# HSM_HSM_PKE_CE010000h register map
Vendor: Texas Instruments
Peripheral module from a debugger description file (folder AM261x).
Registers are 32-bit, read-only, reset 0x0 unless marked. A register's access mark holds for its fields unless they carry their own. Offsets are as the file gives them; lines under a group give offsets from that group; [hi:lo] are bit positions; {n}, {i} and the like mark numbered series; 'fields as' and 'values as' point back to an identical list; <NAME> marks a mode.

## HSM_PKE
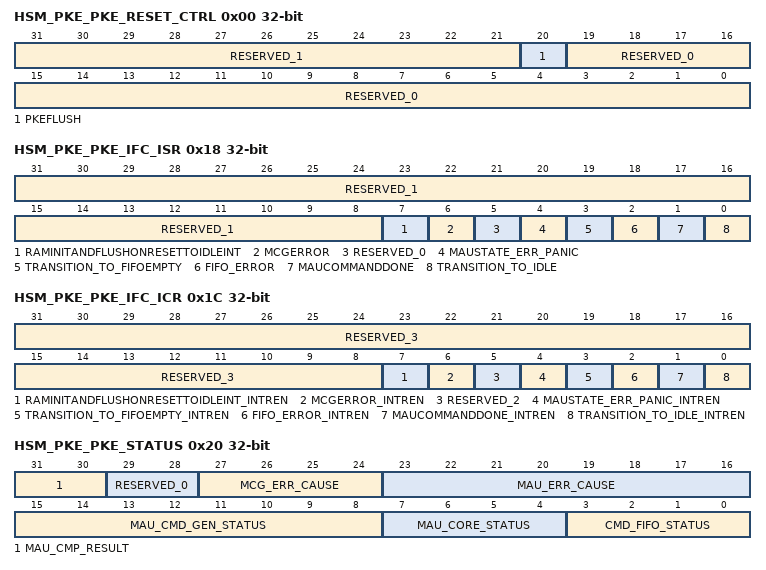
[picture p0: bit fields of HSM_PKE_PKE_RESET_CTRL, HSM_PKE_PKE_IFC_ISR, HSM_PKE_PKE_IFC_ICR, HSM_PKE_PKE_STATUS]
0x00 HSM_PKE_PKE_RESET_CTRL access per field — Reset control for Command FIFO and flush control for MAU Core. This register is not self-clearing.
  [31:21] RESERVED_1 wo — Set to zero on Write, ignore on Read.
  [20] PKEFLUSH rw — pkeFlush input to PKE[active high]. When set, this bit will assert the mauFlush input to MAU Core, resets command FIFO, issues reset to MCG. Flush sequence will complete some cycles after this bit is cleared. PKE will remain in flush state as long as this bit is asserted
  [19:0] RESERVED_0 wo — Set to zero on Write, ignore on Read.
0x18 HSM_PKE_PKE_IFC_ISR access per field — Interrupt Status Register. Writing a 1 to any bit in this register clears the associated interrupt.Cleared on pkeFlush.
  [31:8] RESERVED_1 wo — Set to zero on Write, ignore on Read.
  [7] RAMINITANDFLUSHONRESETTOIDLEINT rw — Asserted when SRAM initialization [when enabled] or FLUSH sequence after reset are completed. The PKE core will go into IDLE state when SRAM initialization [when enabled] and FLUSH sequence after resset finish.
  [6] MCGERROR rw — Asserted when MCG status indicates ERROR/PANIC. This interrupt is re-asserted when cleared if MCG status is MCG_ERROR/PANIC in PKE_STATUS register
  [5] RESERVED_0 wo — Set to zero on Write, ignore on Read.
  [4] MAUSTATE_ERR_PANIC rw — This interrupt is re-asserted when cleared if MAU Core Status is ERROR/PANIC in PKE_STATUS register.
  [3] TRANSITION_TO_FIFOEMPTY rw — This interrupt is asserted when FIFO transitions to empty. fifoEmpty gets asserted when pkeFlush is issued to the core triggering this interrupt. To disable interrupt just after pkeFlush, user can mask the corresponding bit in PKE_IFC_ICR register
  [2] FIFO_ERROR rw — This interrupt is re-asserted when cleared if FIFO Write Error is asserted in PKE_STATUS register.
  [1] MAUCOMMANDDONE rw — This interrupt is asserted when MAU status transition from BUSY to READY/ERROR/PANIC.
  [0] TRANSITION_TO_IDLE rw — Interrupt is generated on transition to idle [FIFO Empty and ![mauState==BUSY] & ![mcgState==BUSY]]
0x1C HSM_PKE_PKE_IFC_ICR access per field — Interrupt Control Register. Writing a 1 to any bit in this register enables the associated interrupt.
  [31:8] RESERVED_3 wo — Set to zero on Write, ignore on Read
  [7] RAMINITANDFLUSHONRESETTOIDLEINT_INTREN rw — Writing a 1 to any bit enables ram init and flush on reset to idle interrupt
  [6] MCGERROR_INTREN rw — Writing a 1 to any bit enables MCG Error interrupt
  [5] RESERVED_2 wo — Set to zero on Write, ignore on Read.
  [4] MAUSTATE_ERR_PANIC_INTREN rw — Writing a 1 to any bit enables MAU state is error panic interrupt
  [3] TRANSITION_TO_FIFOEMPTY_INTREN rw — Writing a 1 to any bit enables transition to FIFO empty interrupt
  [2] FIFO_ERROR_INTREN rw — Writing a 1 to any bit enables FIFO Error interrupt
  [1] MAUCOMMANDDONE_INTREN rw — Writing a 1 to any bit enables MAU command done interrupt
  [0] TRANSITION_TO_IDLE_INTREN rw — Writing a 1 to any bit enables transition to idle interrupt
0x20 HSM_PKE_PKE_STATUS access per field — Reports the status of the Command FIFO, Mau Core, and Mau Command Generator.
  [31:30] MAU_CMP_RESULT ro — Reflects the status of compare result when compare command is completed by MAU core only when the MAU command is issued by AHB. Will be cleared on pkeFlush.
  [29:28] RESERVED_0 wo — Set to zero on Write, ignore on Read.
  [27:24] MCG_ERR_CAUSE ro — MCG currently does not advertise error cause. Will be cleared on pkeFlush.
  [23:16] MAU_ERR_CAUSE ro
  [15:8] MAU_CMD_GEN_STATUS ro — This reflects the command generator unit status. Cleared when MCG Status is error and pkeFlush is issued. 0x0: MCG_IDLE 0x1: MCG_BUSY 0x4: MCG_ERROR 0x8: MCG_PANIC
  [7:4] MAU_CORE_STATUS ro — MAU Core Status State 0x0 : MAU_READY 0x1: MAU_BUSY 0x2: MAU_ERROR 0x8: MAU_PANIC Cleared when MAU Core Status is error and pkeFlush is issued.
  [3:0] CMD_FIFO_STATUS ro — This reflects the command FIFO status. Cleared on pkeFlush. 0b0000 FIFO_EMPTY 0b0001 FIFO_NOT_EMPTY 0b0011 FIFO_FULL 0b01xx FIFO_ERROR
0x30 HSM_PKE_PKE_SCRATCH rw reset 0x76543210 — Scratch register for testing connectivity.
  [31:0] MAU_IFC_SCRATCH — On reset, this value is 0x7654_3210.
0x34 HSM_PKE_MAU_MIN_LEN reset 0x3 — Specifies the minimum length of commands.
  [31:0] MAU_MIN_LEN — This constant register always gives the value of the constant MAU_MIN_LEN.
0x38 HSM_PKE_MAU_MAX_LEN reset 0x40 — Specifies the maximum length of commands.
  [31:0] MAU_MAX_LEN — This constant register always gives the value of the constant MAU_MAX_LEN.
0x3C HSM_PKE_PKE_VERSION reset 0x4 — Specifies the PKE version.
  [31:0] PKE_VERSION — This constant register always gives the version of PKE
0x40 HSM_PKE_MCG_COMMANDS_ENABLED_0 reset 0xFC5FFFFF — Specifies the MCG commands enabled.
  [31:0] MCG_COMMAND_ENABLED — This constant register gives the commands enabled for MCG in the current version.
0x44 HSM_PKE_MCG_COMMANDS_ENABLED_1 reset 0x3E — Specifies the MCG commands enabled.
  fields as HSM_PKE_MCG_COMMANDS_ENABLED_0
0x48 HSM_PKE_MCG_COMMANDS_ENABLED_2 — Specifies the MCG commands enabled.
  fields as HSM_PKE_MCG_COMMANDS_ENABLED_0
0x4C HSM_PKE_MCG_COMMANDS_ENABLED_3 — Specifies the MCG commands enabled.
  fields as HSM_PKE_MCG_COMMANDS_ENABLED_0
{0x50+4i} HSM_PKE_PKE_PRNG_SEED_{i} wo (i=0..3) — Register to (re)seed PRNG.
  [31:0] PKE_PRNG_SEED — When written all 128 bits in this register will reseed PRNG inside PKE. The reseed happens when register at 0x5C is written. So, it is important to write 0x50, 0x54, 0x58 before Writing 0x5C. Reseed completes in one cycle, so no status is returned. The register value at 0x50 forms the lowest word of 128 bits and register at 0x5C forms the highest word of 128 bits seed. Reseed vale is {pkePrngSeed[0x5C], pkePrngSeed[0x58], pkePrngSeed[0x54], pkePrngSeed[0x50]
0x60 HSM_PKE_PKE_WORD_SIZE reset 0x40 — Specifies the datapath configuration of the PKE core (32x32, 64x64).
  [31:0] PKE_WORD_SIZE — This constant register always gives the value of constant MAU_WORD 0x40: MAU_WORD=64 0x20: MAU_WORD=32
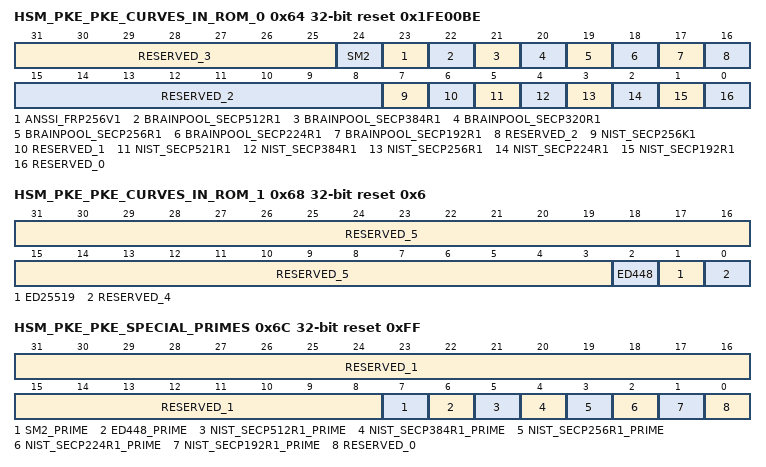
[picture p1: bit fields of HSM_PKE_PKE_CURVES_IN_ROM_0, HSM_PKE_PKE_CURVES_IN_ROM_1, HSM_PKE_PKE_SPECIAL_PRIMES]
0x64 HSM_PKE_PKE_CURVES_IN_ROM_0 reset 0x1FE00BE — Specifies the curves that are supported in ROM.
  [31:25] RESERVED_3 — Constant will be read as 'b0 always
  [24] SM2 — Constant value which gives the value of SM2 support
  [23] ANSSI_FRP256V1 — Constant value which gives the value of ANSSI FRP256V1 support
  [22] BRAINPOOL_SECP512R1 — Constant value which gives the value of Brainpool secp512r1 support
  [21] BRAINPOOL_SECP384R1 — Constant value which gives the value of Brainpool secp384r1 support
  [20] BRAINPOOL_SECP320R1 — Constant value which gives the value of Brainpool secp320r1 support
  [19] BRAINPOOL_SECP256R1 — Constant value which gives the value of Brainpool secp256r1 support
  [18] BRAINPOOL_SECP224R1 — Constant value which gives the value of Brainpool secp224r1 support
  [17] BRAINPOOL_SECP192R1 — Constant value which gives the value of Brainpool secp192r1 support
  [16:8] RESERVED_2 — Constant will be read as 'b0 always
  [7] NIST_SECP256K1 — Constant value which gives the value of NIST secp256k1 support
  [6] RESERVED_1 — Constant will be read as 'b0 always
  [5] NIST_SECP521R1 — Constant value which gives the value of NIST secp512r1 support
  [4] NIST_SECP384R1 — Constant value which gives the value of NIST secp384r1 support
  [3] NIST_SECP256R1 — Constant value which gives the value of NIST secp256r1 support
  [2] NIST_SECP224R1 — Constant value which gives the value of NIST secp224r1 support
  [1] NIST_SECP192R1 — Constant value which gives the value of NIST secp192r1 support
  [0] RESERVED_0 — Constant will be read as 'b0 always
0x68 HSM_PKE_PKE_CURVES_IN_ROM_1 reset 0x6 — Specifies the curves that are supported in ROM.
  [31:3] RESERVED_5 — Constant will be read as 'b0 always
  [2] ED448 — Constant value which gives the value of ED448 support
  [1] ED25519 — Constant value which gives the value of ED25519 support
  [0] RESERVED_4 — Constant will be read as 'b0 always
0x6C HSM_PKE_PKE_SPECIAL_PRIMES reset 0xFF — Specifies the curves with special primes which have special prime unit implemented.
  [31:8] RESERVED_1 — Constant will be read as 'b0 always
  [7] SM2_PRIME — Constant value which gives the value MCG prime support for SM2
  [6] ED448_PRIME — Constant value which gives the value MCG prime support for Ed448
  [5] NIST_SECP512R1_PRIME — Constant value which gives the value MCG prime support for NIST secp512r1
  [4] NIST_SECP384R1_PRIME — Constant value which gives the value MCG prime support for NIST secp384r1
  [3] NIST_SECP256R1_PRIME — Constant value which gives the value MCG prime support for NIST secp256r1
  [2] NIST_SECP224R1_PRIME — Constant value which gives the value MCG prime support for NIST secp224r1
  [1] NIST_SECP192R1_PRIME — Constant value which gives the value MCG prime support for NIST secp192r1
  [0] RESERVED_0 — Constant will be read as 'b1 always
0x70 HSM_PKE_PKE_SRAM_ADDR_MIN — Specifies the minimum SRAM address.
  [31:0] PKE_SRAM_ADDR — This constant bitfield gives the value of mauWcMemMinAddrConst
0x74 HSM_PKE_PKE_SRAM_ADDR_MAX reset 0x1FF — Species the maximum SRAM address.
  [31:0] PKE_SRAM_ADDR — This constant bitfield gives the value of mauWcMemMaxAddrConst
0x80 HSM_PKE_MAU_COMMAND wo — MAU command word. Writing to this address queues an update to the mauCommandIn register.
  [31:0] MAUCOMMANDIN
0x88 HSM_PKE_MAU_MCG_COMMAND wo — Writes to this address will start a new operation in MCG. Writes are queued in Command Register Queue and will complete only when generator is ready to accept a new command.
  [31:0] MAUCMDGENCOMMAND
